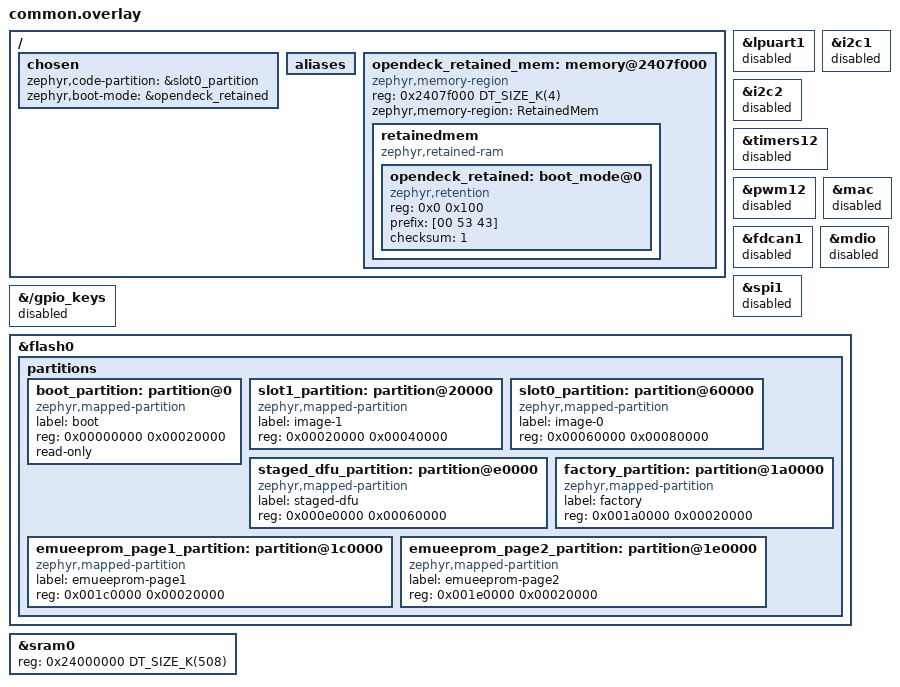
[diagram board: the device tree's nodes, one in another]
/ {
    chosen {
        /delete-property/ zephyr,canbus;
    };
};

&lpuart1 {
    status = "disabled";
};

&i2c1 {
    status = "disabled";
};

&i2c2 {
    status = "disabled";
};

&timers12 {
    status = "disabled";
};

&pwm12 {
    status = "disabled";
};

&fdcan1 {
    status = "disabled";
};

&mac {
    status = "disabled";
};

&mdio {
    status = "disabled";
};

&spi1 {
    status = "disabled";
};

&{/gpio_keys} {
    status = "disabled";
};

/ {
    aliases {
        /delete-property/ led0;
        /delete-property/ led1;
        /delete-property/ pwm-led0;
    };

    /delete-node/ leds;
    /delete-node/ pwmleds;
};

&flash0 {
    #address-cells = <1>;
    #size-cells = <1>;
    ranges = <0x0 0x08000000 0x00200000>;

    partitions {
        ranges;
        #address-cells = <1>;
        #size-cells = <1>;

        /delete-node/ partition@0;
        /delete-node/ partition@20000;
        /delete-node/ partition@60000;
        /delete-node/ partition@c0000;
        /delete-node/ partition@e0000;

        boot_partition: partition@0 {
            compatible = "zephyr,mapped-partition";
            label = "boot";
            reg = <0x00000000 0x00020000>;
            read-only;
        };

        /* image-1 is the OpenDeck bootloader; keep it before image-0 so merged images stay compact. */
        slot1_partition: partition@20000 {
            compatible = "zephyr,mapped-partition";
            label = "image-1";
            reg = <0x00020000 0x00040000>;
        };

        slot0_partition: partition@60000 {
            compatible = "zephyr,mapped-partition";
            label = "image-0";
            reg = <0x00060000 0x00080000>;
        };

        staged_dfu_partition: partition@e0000 {
            compatible = "zephyr,mapped-partition";
            label = "staged-dfu";
            reg = <0x000e0000 0x00060000>;
        };

        factory_partition: partition@1a0000 {
            compatible = "zephyr,mapped-partition";
            label = "factory";
            reg = <0x001a0000 0x00020000>;
        };

        emueeprom_page1_partition: partition@1c0000 {
            compatible = "zephyr,mapped-partition";
            label = "emueeprom-page1";
            reg = <0x001c0000 0x00020000>;
        };

        emueeprom_page2_partition: partition@1e0000 {
            compatible = "zephyr,mapped-partition";
            label = "emueeprom-page2";
            reg = <0x001e0000 0x00020000>;
        };
    };
};

&sram0 {
    reg = <0x24000000 DT_SIZE_K(508)>;
};

/ {
    chosen {
        zephyr,code-partition = &slot0_partition;
        zephyr,boot-mode = &opendeck_retained;
    };

    opendeck_retained_mem: memory@2407f000 {
        compatible = "zephyr,memory-region", "mmio-sram";
        reg = <0x2407f000 DT_SIZE_K(4)>;
        zephyr,memory-region = "RetainedMem";
        status = "okay";

        retainedmem {
            compatible = "zephyr,retained-ram";
            status = "okay";
            #address-cells = <1>;
            #size-cells = <1>;

            opendeck_retained: boot_mode@0 {
                compatible = "zephyr,retention";
                status = "okay";
                reg = <0x0 0x100>;
                prefix = [00 53 43];
                checksum = <1>;
            };
        };
    };
};
